AUTOSAR XML (schema 4-2-2)
package /ComponentTypes
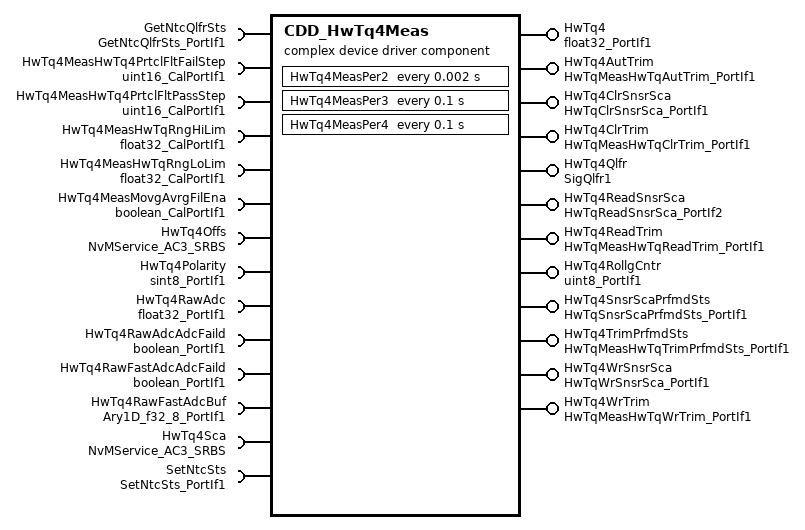
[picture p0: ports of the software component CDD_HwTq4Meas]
  complex device driver sw component type CDD_HwTq4Meas
    12 x provide port:
      HwTq4: nonqueued-sender-com-spec{data-element=Val, init-value=0}, provided-interface=float32_PortIf1
      HwTq4AutTrim: server-com-spec{operation=Oper, queue-length=1}, provided-interface=HwTqMeasHwTqAutTrim_PortIf1
      HwTq4ClrSnsrSca: server-com-spec{operation=Oper, queue-length=1}, provided-interface=HwTqClrSnsrSca_PortIf1
      HwTq4ClrTrim: server-com-spec{operation=Oper, queue-length=1}, provided-interface=HwTqMeasHwTqClrTrim_PortIf1
      HwTq4Qlfr: nonqueued-sender-com-spec{data-element=Val, init-value=0}, provided-interface=SigQlfr1
      HwTq4ReadSnsrSca: server-com-spec{operation=Oper, queue-length=1}, provided-interface=HwTqReadSnsrSca_PortIf2
      HwTq4ReadTrim: server-com-spec{operation=Oper, queue-length=1}, provided-interface=HwTqMeasHwTqReadTrim_PortIf1
      HwTq4RollgCntr: nonqueued-sender-com-spec{data-element=Val, init-value=0}, provided-interface=uint8_PortIf1
      HwTq4SnsrScaPrfmdSts: server-com-spec{operation=Oper, queue-length=1}, provided-interface=HwTqSnsrScaPrfmdSts_PortIf1
      HwTq4TrimPrfmdSts: server-com-spec{operation=Oper, queue-length=1}, provided-interface=HwTqMeasHwTqTrimPrfmdSts_PortIf1
      HwTq4WrSnsrSca: server-com-spec{operation=Oper, queue-length=1}, provided-interface=HwTqWrSnsrSca_PortIf1
      HwTq4WrTrim: server-com-spec{operation=Oper, queue-length=1}, provided-interface=HwTqMeasHwTqWrTrim_PortIf1
    14 x require port:
      GetNtcQlfrSts: client-com-spec=Oper, required-interface=GetNtcQlfrSts_PortIf1
      HwTq4MeasHwTq4PrtclFltFailStep: parameter-require-com-spec{init-value=2521, parameter=Val}, required-interface=uint16_CalPortIf1
      HwTq4MeasHwTq4PrtclFltPassStep: parameter-require-com-spec{init-value=1000, parameter=Val}, required-interface=uint16_CalPortIf1
      HwTq4MeasHwTqRngHiLim: parameter-require-com-spec{init-value=4.75, parameter=Val}, required-interface=float32_CalPortIf1
      HwTq4MeasHwTqRngLoLim: parameter-require-com-spec{init-value=0.25, parameter=Val}, required-interface=float32_CalPortIf1
      HwTq4MeasMovgAvrgFilEna: parameter-require-com-spec{init-value=0, parameter=Logl}, required-interface=boolean_CalPortIf1
      HwTq4Offs: required-com-specs=[EraseBlock, GetErrorStatus, InvalidateNvBlock, ReadBlock, SetRamBlockStatus, WriteBlock], required-interface=NvMService_AC3_SRBS
      HwTq4Polarity: nonqueued-receiver-com-spec{data-element=Val, filter=data-filter-type=ALWAYS, init-value=1}, required-interface=sint8_PortIf1
      HwTq4RawAdc: nonqueued-receiver-com-spec{data-element=Val, filter=data-filter-type=ALWAYS, init-value=0}, required-interface=float32_PortIf1
      HwTq4RawAdcAdcFaild: nonqueued-receiver-com-spec{data-element=Logl, filter=data-filter-type=ALWAYS, init-value=0}, required-interface=boolean_PortIf1
      HwTq4RawFastAdcAdcFaild: nonqueued-receiver-com-spec{data-element=Logl, filter=data-filter-type=ALWAYS, init-value=0}, required-interface=boolean_PortIf1
      HwTq4RawFastAdcBuf: nonqueued-receiver-com-spec{data-element=Ary1D, filter=data-filter-type=ALWAYS, init-value=8 x 0}, required-interface=Ary1D_f32_8_PortIf1
      HwTq4Sca: required-com-specs=[EraseBlock, GetErrorStatus, InvalidateNvBlock, ReadBlock, SetRamBlockStatus, WriteBlock], required-interface=NvMService_AC3_SRBS
      SetNtcSts: client-com-spec=Oper, required-interface=SetNtcSts_PortIf1
    behavior CDD_HwTq4Meas_InternalBehavior
      ar-typed-per-instance-memorys:
        5 x data, all with sw-calibration-access=READ-ONLY:
          HwTq4Offs: type=HwTqOffsRec1
          HwTq4PrevHwTq4: type=float32
          HwTq4PrevRollgCntr: type=uint8
          HwTq4RawFastAdcIdxCntr: type=uint8
          HwTq4Sca: type=AnHwTqScaFacRec1
      operation invoked event OIT_HwTq4AutTrim_Oper_HwTq4AutTrim_Oper: start-on-event=HwTq4AutTrim_Oper, operation=HwTq4AutTrim.Oper
      operation invoked event OIT_HwTq4ClrSnsrSca_Oper_HwTq4ClrSnsrSca_Oper: start-on-event=HwTq4ClrSnsrSca_Oper, operation=HwTq4ClrSnsrSca.Oper
      operation invoked event OIT_HwTq4ClrTrim_Oper_HwTq4ClrTrim_Oper: start-on-event=HwTq4ClrTrim_Oper, operation=HwTq4ClrTrim.Oper
      init event HwTq4Meas_InitEvent: start-on-event=HwTq4MeasInit1
      timing event TMT_HwTq4MeasPer2: start-on-event=HwTq4MeasPer2, period=0.002
      timing event TMT_HwTq4MeasPer3: start-on-event=HwTq4MeasPer3, period=0.1
      timing event TMT_HwTq4MeasPer4: start-on-event=HwTq4MeasPer4, period=0.1
      6 x operation invoked event:
        OIT_HwTq4ReadSnsrSca_Oper_HwTq4ReadSnsrSca_Oper: start-on-event=HwTq4ReadSnsrSca_Oper, operation=HwTq4ReadSnsrSca.Oper
        OIT_HwTq4ReadTrim_Oper_HwTq4ReadTrim_Oper: start-on-event=HwTq4ReadTrim_Oper, operation=HwTq4ReadTrim.Oper
        OIT_HwTq4SnsrScaPrfmdSts_Oper_HwTq4SnsrScaPrfmdSts_Oper: start-on-event=HwTq4SnsrScaPrfmdSts_Oper, operation=HwTq4SnsrScaPrfmdSts.Oper
        OIT_HwTq4TrimPrfmdSts_Oper_HwTq4TrimPrfmdSts_Oper: start-on-event=HwTq4TrimPrfmdSts_Oper, operation=HwTq4TrimPrfmdSts.Oper
        OIT_HwTq4WrSnsrSca_Oper_HwTq4WrSnsrSca_Oper: start-on-event=HwTq4WrSnsrSca_Oper, operation=HwTq4WrSnsrSca.Oper
        OIT_HwTq4WrTrim_Oper_HwTq4WrTrim_Oper: start-on-event=HwTq4WrTrim_Oper, operation=HwTq4WrTrim.Oper
      13 x runnable:
        HwTq4AutTrim_Oper
          sync call SC_HwTq4Offs_SetRamBlockStatus: operation=HwTq4Offs.SetRamBlockStatus, timeout=0
        HwTq4ClrSnsrSca_Oper
          sync call SC_HwTq4Sca_SetRamBlockStatus: operation=HwTq4Sca.SetRamBlockStatus, timeout=0
        HwTq4ClrTrim_Oper
          sync call SC_HwTq4Offs_SetRamBlockStatus: operation=HwTq4Offs.SetRamBlockStatus, timeout=0
        HwTq4MeasInit1
          sync call SC_HwTq4Offs_GetErrorStatus: operation=HwTq4Offs.GetErrorStatus, timeout=0
          sync call SC_HwTq4Sca_GetErrorStatus: operation=HwTq4Sca.GetErrorStatus, timeout=0
        HwTq4MeasPer2
          data-receive-point-by-arguments:
            5 x access:
              REC_HwTq4FastAdcBuf_Ary1D: accessed-variable=HwTq4RawFastAdcBuf.Ary1D
              REC_HwTq4Polarity_Val: accessed-variable=HwTq4Polarity.Val
              REC_HwTq4RawAdc_Val: accessed-variable=HwTq4RawAdc.Val
              REC_HwTq4RawAdcAdcFaild_Logl: accessed-variable=HwTq4RawAdcAdcFaild.Logl
              REC_HwTq4RawFastAdcAdcFaild_Logl: accessed-variable=HwTq4RawFastAdcAdcFaild.Logl
          data-send-points:
            access SEND_HwTq4_Val: accessed-variable=HwTq4.Val
            access SEND_HwTq4Qlfr_Val: accessed-variable=HwTq4Qlfr.Val
            access SEND_HwTq4RollgCntr_Val: accessed-variable=HwTq4RollgCntr.Val
          sync call SC_GetNtcQlfrSts_Oper: operation=GetNtcQlfrSts.Oper, timeout=0
          sync call SC_SetNtcSts_Oper: operation=SetNtcSts.Oper, timeout=0
        HwTq4MeasPer3
          sync call SC_SetNtcSts_Oper: operation=SetNtcSts.Oper, timeout=0
        HwTq4MeasPer4
          sync call SC_SetNtcSts_Oper: operation=SetNtcSts.Oper, timeout=0
        HwTq4ReadSnsrSca_Oper
        HwTq4ReadTrim_Oper
        HwTq4SnsrScaPrfmdSts_Oper
        HwTq4TrimPrfmdSts_Oper
        HwTq4WrSnsrSca_Oper
          sync call SC_HwTq4Sca_SetRamBlockStatus: operation=HwTq4Sca.SetRamBlockStatus, timeout=0
        HwTq4WrTrim_Oper
          sync call SC_HwTq4Offs_SetRamBlockStatus: operation=HwTq4Offs.SetRamBlockStatus, timeout=0
      swc service dependency NvmHwTq4Offs: assigned-datas=role-based-data-assignment={role=ramBlock, used-data-element=HwTq4Offs}, assigned-ports=role-based-port-assignment={port-prototype=HwTq4Offs, role=NvMService_AC3_SRBS}
        service-needs:
          nv block needs NvmHwTq4Offs: n-data-sets=0, ram-block-status-control=API, readonly=false, reliability=ERROR-DETECTION, resistant-to-changed-sw=true, restore-at-start=true, store-at-shutdown=true, write-only-once=false, writing-frequency=0, writing-priority=LOW
      swc service dependency NvmHwTq4Sca: assigned-datas=role-based-data-assignment={role=ramBlock, used-data-element=HwTq4Sca}, assigned-ports=role-based-port-assignment={port-prototype=HwTq4Sca, role=NvMService_AC3_SRBS}
        service-needs:
          nv block needs NvmHwTq4Sca: n-data-sets=0, ram-block-status-control=API, readonly=false, reliability=ERROR-DETECTION, resistant-to-changed-sw=true, restore-at-start=true, store-at-shutdown=true, write-only-once=false, writing-frequency=0, writing-priority=LOW
  swc implementation CDD_HwTq4Meas_Implementation: behavior=CDD_HwTq4Meas_InternalBehavior
    code-descriptors:
      code Default: artifact-descriptors=autosar-engineering-object={short-label=Default, category=SWSRC}
